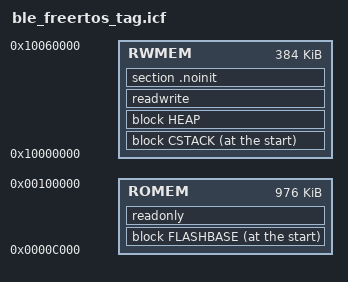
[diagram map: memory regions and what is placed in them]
//*****************************************************************************
//
// ble_freertos_tag.icf
//
// IAR linker Configuration File
//
//*****************************************************************************

//*****************************************************************************
//
// Copyright (c) 2023, Ambiq Micro, Inc.
// All rights reserved.
//
// Redistribution and use in source and binary forms, with or without
// modification, are permitted provided that the following conditions are met:
//
// 1. Redistributions of source code must retain the above copyright notice,
// this list of conditions and the following disclaimer.
//
// 2. Redistributions in binary form must reproduce the above copyright
// notice, this list of conditions and the following disclaimer in the
// documentation and/or other materials provided with the distribution.
//
// 3. Neither the name of the copyright holder nor the names of its
// contributors may be used to endorse or promote products derived from this
// software without specific prior written permission.
//
// Third party software included in this distribution is subject to the
// additional license terms as defined in the /docs/licenses directory.
//
// THIS SOFTWARE IS PROVIDED BY THE COPYRIGHT HOLDERS AND CONTRIBUTORS "AS IS"
// AND ANY EXPRESS OR IMPLIED WARRANTIES, INCLUDING, BUT NOT LIMITED TO, THE
// IMPLIED WARRANTIES OF MERCHANTABILITY AND FITNESS FOR A PARTICULAR PURPOSE
// ARE DISCLAIMED. IN NO EVENT SHALL THE COPYRIGHT HOLDER OR CONTRIBUTORS BE
// LIABLE FOR ANY DIRECT, INDIRECT, INCIDENTAL, SPECIAL, EXEMPLARY, OR
// CONSEQUENTIAL DAMAGES (INCLUDING, BUT NOT LIMITED TO, PROCUREMENT OF
// SUBSTITUTE GOODS OR SERVICES; LOSS OF USE, DATA, OR PROFITS; OR BUSINESS
// INTERRUPTION) HOWEVER CAUSED AND ON ANY THEORY OF LIABILITY, WHETHER IN
// CONTRACT, STRICT LIABILITY, OR TORT (INCLUDING NEGLIGENCE OR OTHERWISE)
// ARISING IN ANY WAY OUT OF THE USE OF THIS SOFTWARE, EVEN IF ADVISED OF THE
// POSSIBILITY OF SUCH DAMAGE.
//
// This is part of revision release_sdk_3_1_1-10cda4b5e0 of the AmbiqSuite Development Package.
//
//*****************************************************************************

//
// Define a memory section that covers the entire 4 GB addressable space of the
// processor. (32-bit can address up to 4GB)
//
define memory mem with size = 4G;

//
// Define regions for the various types of internal memory.
//
define region ROMEM    = mem:[from 0x0000C000 to 0x00100000];
define region RWMEM    = mem:[from 0x10000000 to 0x10060000];

//
// Define blocks for logical groups of data.
//
define block HEAP with alignment = 0x8, size = 0x00000000 { };
define block CSTACK with alignment = 0x8, size = 11008
{
    section .stack
};

define block FLASHBASE with fixed order
{
    readonly section .intvec,
    readonly section .patch
};

//
// Set section properties.
//
initialize by copy { readwrite };
do not initialize { section .noinit };
do not initialize { section .stack };

//
// Place code sections in memory regions.
//
place at start of ROMEM { block FLASHBASE };
place in ROMEM { readonly };
place at start of RWMEM { block CSTACK};
place in RWMEM { block HEAP, readwrite, section .noinit };

